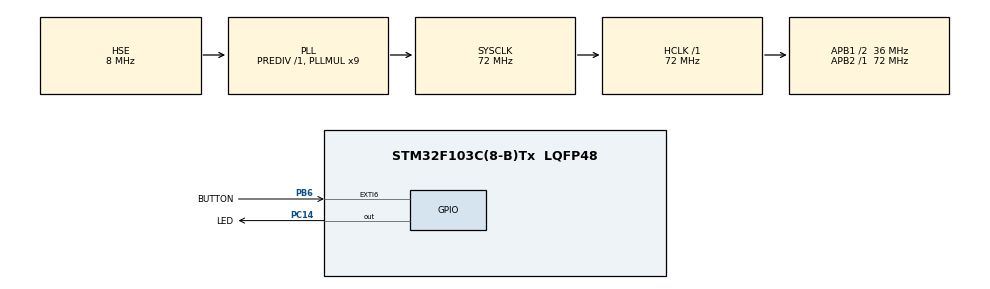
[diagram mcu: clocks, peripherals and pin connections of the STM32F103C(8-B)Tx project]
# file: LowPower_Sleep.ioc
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Mcu.Family=STM32F1
Mcu.Name=STM32F103C(8-B)Tx
Mcu.Package=LQFP48
NVIC.EXTI9_5_IRQn=true\:0\:0\:false\:false\:true\:true\:true\:true
NVIC.PriorityGroup=NVIC_PRIORITYGROUP_4
NVIC.RTC_Alarm_IRQn=true\:0\:0\:false\:false\:true\:true\:true\:true
PA13.Mode=Trace_Asynchronous_SW
PA13.Signal=SYS_JTMS-SWDIO
PA14.Mode=Trace_Asynchronous_SW
PA14.Signal=SYS_JTCK-SWCLK
PB3.Mode=Trace_Asynchronous_SW
PB3.Signal=SYS_JTDO-TRACESWO
PB6.GPIO_Label=BUTTON
PB6.GPIO_PuPd=GPIO_PULLUP
PB6.Signal=GPXTI6
PC14-OSC32_IN.GPIO_Label=LED
PC14-OSC32_IN.Signal=GPIO_Output
PD0-OSC_IN.Mode=HSE-External-Oscillator
PD0-OSC_IN.Signal=RCC_OSC_IN
PD1-OSC_OUT.Mode=HSE-External-Oscillator
PD1-OSC_OUT.Signal=RCC_OSC_OUT
ProjectManager.HeapSize=0x200
ProjectManager.StackSize=0x400
ProjectManager.TargetToolchain=STM32CubeIDE
RCC.AHBFreq_Value=72000000
RCC.APB1CLKDivider=RCC_HCLK_DIV2
RCC.APB1Freq_Value=36000000
RCC.APB1TimFreq_Value=72000000
RCC.APB2Freq_Value=72000000
RCC.APB2TimFreq_Value=72000000
RCC.HCLKFreq_Value=72000000
RCC.PLLMUL=RCC_PLL_MUL9
RCC.PLLSourceVirtual=RCC_PLLSOURCE_HSE
RCC.SYSCLKFreq_VALUE=72000000
RCC.SYSCLKSource=RCC_SYSCLKSOURCE_PLLCLK
RCC.USBFreq_Value=72000000
VP_RTC_VS_RTC_Activate.Mode=RTC_Enabled
board=custom

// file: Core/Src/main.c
/* USER CODE BEGIN Header */
/**
  ******************************************************************************
  * @file           : main.c
  * @brief          : Main program body
  ******************************************************************************
  * @attention
  *
  * Copyright (c) 2024 STMicroelectronics.
  * All rights reserved.
  *
  * This software is licensed under terms that can be found in the LICENSE file
  * in the root directory of this software component.
  * If no LICENSE file comes with this software, it is provided AS-IS.
  *
  ******************************************************************************
  */
/* USER CODE END Header */
#include "main.h"

RTC_HandleTypeDef hrtc;

void SystemClock_Config(void);
static void MX_GPIO_Init(void);
static void MX_RTC_Init(void);
/* USER CODE BEGIN PFP */
void HAL_GPIO_EXTI_Callback(uint16_t GPIO_Pin);
void HAL_RTC_AlarmAEventCallback(RTC_HandleTypeDef *hrtc);
/* USER CODE END PFP */

int main(void)
{

  /* MCU Configuration--------------------------------------------------------*/

  /* Reset of all peripherals, Initializes the Flash interface and the Systick. */
  HAL_Init();

  /* Configure the system clock */
  SystemClock_Config();

  /* Initialize all configured peripherals */
  MX_GPIO_Init();
  MX_RTC_Init();

  /* Infinite loop */
  /* USER CODE BEGIN WHILE */
  while (1)
  {
	for(uint8_t i = 0; i < 5; i++) {
		HAL_GPIO_TogglePin(LED_GPIO_Port, LED_Pin);
		HAL_Delay(200);
	}
	HAL_GPIO_WritePin(LED_GPIO_Port, LED_Pin, GPIO_PIN_SET);
	ITM_SendChar('1');
	ITM_SendChar('\n');

	RTC_TimeTypeDef sTime = {0};
	sTime.Hours = 0x0;
	sTime.Minutes = 0x0;
	sTime.Seconds = 0x0;

	if (HAL_RTC_SetTime(&hrtc, &sTime, RTC_FORMAT_BCD) != HAL_OK)
	{
		Error_Handler();
	}

	RTC_AlarmTypeDef sAlarm;
	sAlarm.AlarmTime.Hours = 0;
	sAlarm.AlarmTime.Minutes = 0;
	sAlarm.AlarmTime.Seconds = 10;
	HAL_RTC_SetAlarm_IT(&hrtc, &sAlarm, FORMAT_BCD);

	HAL_SuspendTick();

	HAL_PWR_EnableSleepOnExit();

//	  Enter Sleep Mode , wake up is done once User push-button is pressed
	HAL_PWR_EnterSLEEPMode(PWR_MAINREGULATOR_ON, PWR_SLEEPENTRY_WFI);

//	Resume Tick interrupt if disabled prior to sleep mode entry
	HAL_ResumeTick();

	for(uint8_t i = 0; i < 5; i++) {
		HAL_GPIO_TogglePin(LED_GPIO_Port, LED_Pin);
		HAL_Delay(200);
	}
	HAL_GPIO_WritePin(LED_GPIO_Port, LED_Pin, GPIO_PIN_RESET);
	ITM_SendChar('2');
	ITM_SendChar('\n');

	HAL_Delay(2000);
    /* USER CODE END WHILE */

  }
}

void SystemClock_Config(void)
{
  RCC_OscInitTypeDef RCC_OscInitStruct = {0};
  RCC_ClkInitTypeDef RCC_ClkInitStruct = {0};
  RCC_PeriphCLKInitTypeDef PeriphClkInit = {0};

  /** Initializes the RCC Oscillators according to the specified parameters
  * in the RCC_OscInitTypeDef structure.
  */
  RCC_OscInitStruct.OscillatorType = RCC_OSCILLATORTYPE_LSI|RCC_OSCILLATORTYPE_HSE;
  RCC_OscInitStruct.HSEState = RCC_HSE_ON;
  RCC_OscInitStruct.HSEPredivValue = RCC_HSE_PREDIV_DIV1;
  RCC_OscInitStruct.HSIState = RCC_HSI_ON;
  RCC_OscInitStruct.LSIState = RCC_LSI_ON;
  RCC_OscInitStruct.PLL.PLLState = RCC_PLL_ON;
  RCC_OscInitStruct.PLL.PLLSource = RCC_PLLSOURCE_HSE;
  RCC_OscInitStruct.PLL.PLLMUL = RCC_PLL_MUL9;
  if (HAL_RCC_OscConfig(&RCC_OscInitStruct) != HAL_OK)
  {
    Error_Handler();
  }

  /** Initializes the CPU, AHB and APB buses clocks
  */
  RCC_ClkInitStruct.ClockType = RCC_CLOCKTYPE_HCLK|RCC_CLOCKTYPE_SYSCLK
                              |RCC_CLOCKTYPE_PCLK1|RCC_CLOCKTYPE_PCLK2;
  RCC_ClkInitStruct.SYSCLKSource = RCC_SYSCLKSOURCE_PLLCLK;
  RCC_ClkInitStruct.AHBCLKDivider = RCC_SYSCLK_DIV1;
  RCC_ClkInitStruct.APB1CLKDivider = RCC_HCLK_DIV2;
  RCC_ClkInitStruct.APB2CLKDivider = RCC_HCLK_DIV1;

  if (HAL_RCC_ClockConfig(&RCC_ClkInitStruct, FLASH_LATENCY_2) != HAL_OK)
  {
    Error_Handler();
  }
  PeriphClkInit.PeriphClockSelection = RCC_PERIPHCLK_RTC;
  PeriphClkInit.RTCClockSelection = RCC_RTCCLKSOURCE_LSI;
  if (HAL_RCCEx_PeriphCLKConfig(&PeriphClkInit) != HAL_OK)
  {
    Error_Handler();
  }
}

static void MX_RTC_Init(void)
{

  /** Initialize RTC Only
  */
  hrtc.Instance = RTC;
  hrtc.Init.AsynchPrediv = RTC_AUTO_1_SECOND;
  hrtc.Init.OutPut = RTC_OUTPUTSOURCE_ALARM;
  if (HAL_RTC_Init(&hrtc) != HAL_OK)
  {
    Error_Handler();
  }

}

static void MX_GPIO_Init(void)
{
  GPIO_InitTypeDef GPIO_InitStruct = {0};

  /* GPIO Ports Clock Enable */
  __HAL_RCC_GPIOC_CLK_ENABLE();
  __HAL_RCC_GPIOD_CLK_ENABLE();
  __HAL_RCC_GPIOA_CLK_ENABLE();
  __HAL_RCC_GPIOB_CLK_ENABLE();

  /*Configure GPIO pin Output Level */
  HAL_GPIO_WritePin(LED_GPIO_Port, LED_Pin, GPIO_PIN_RESET);

  /*Configure GPIO pin : LED_Pin */
  GPIO_InitStruct.Pin = LED_Pin;
  GPIO_InitStruct.Mode = GPIO_MODE_OUTPUT_PP;
  GPIO_InitStruct.Pull = GPIO_NOPULL;
  GPIO_InitStruct.Speed = GPIO_SPEED_FREQ_LOW;
  HAL_GPIO_Init(LED_GPIO_Port, &GPIO_InitStruct);

  /*Configure GPIO pin : BUTTON_Pin */
  GPIO_InitStruct.Pin = BUTTON_Pin;
  GPIO_InitStruct.Mode = GPIO_MODE_IT_RISING;
  GPIO_InitStruct.Pull = GPIO_PULLUP;
  HAL_GPIO_Init(BUTTON_GPIO_Port, &GPIO_InitStruct);

  /* EXTI interrupt init*/
  HAL_NVIC_SetPriority(EXTI9_5_IRQn, 0, 0);
  HAL_NVIC_EnableIRQ(EXTI9_5_IRQn);

}

/* USER CODE BEGIN 4 */
void HAL_GPIO_EXTI_Callback(uint16_t GPIO_Pin)
{
	if(GPIO_Pin == BUTTON_Pin) {
		ITM_SendChar('b');
		ITM_SendChar('\n');
		HAL_PWR_DisableSleepOnExit();
	}
}

void HAL_RTC_AlarmAEventCallback(RTC_HandleTypeDef *hrtc) {
	ITM_SendChar('a');
	ITM_SendChar('\n');
}
/* USER CODE END 4 */

void Error_Handler(void)
{
  __disable_irq();
  while (1)
  {
  }
}
